# PIC32CX1025MTSH128S1 register map
Vendor: Microchip Technology; Series: PIC32CXMTSH; File version: 0
CPU: CM4 r0p1, little endian, MPU, FPU, 4 interrupt priority bits, 96 interrupts
Registers are 32-bit, read-write, reset 0x0 unless marked. A register's access mark holds for its fields unless they carry their own. Offsets are from the block's base; [hi:lo] are bit positions; {n}, {i} and the like mark numbered series.

## NVIC — Nested Vectored Interrupt Controller
Base 0xE000E100
{0x0+4i} ISER[{i}] (i=0..7) — Interrupt Set Enable Register
  [31:0] SETENA — Interrupt set enable bits
{0x80+4i} ICER[{i}] (i=0..7) — Interrupt Clear Enable Register
  [31:0] CLRENA — Interrupt clear-enable bits
{0x100+4i} ISPR[{i}] (i=0..7) — Interrupt Set Pending Register
  [31:0] SETPEND — Interrupt set-pending bits
{0x180+4i} ICPR[{i}] (i=0..7) — Interrupt Clear Pending Register
  [31:0] CLRPEND — Interrupt clear-pending bits
{0x200+4i} IABR[{i}] (i=0..7) ro — Interrupt Active bit Register
  [31:0] ACTIVE — Interrupt active flags
{0x300+i} IP[{i}] (i=0..239) 8-bit — Interrupt Priority Register
  [7:0] PRI — Priority of interrupt
0xE00 STIR wo — Software Trigger Interrupt Register
  [8:0] INTID — Indicates the interrupt to be triggered. The value written is (ExceptionNumber - 16)

## SCnSCB — System control not in SCB
Base 0xE000E000
0x04 ICTR ro — Interrupt Controller Type Register
  [3:0] INTLINESNUM — Total number of interrupt lines supported by an implementation, defined in groups of 32
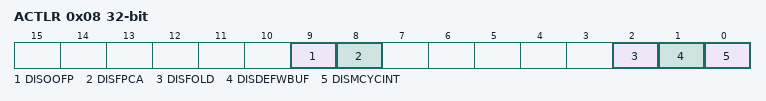
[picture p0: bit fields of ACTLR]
0x08 ACTLR — Auxiliary Control Register
  [9] DISOOFP — Disables floating point instructions completing out of order with respect to integer instructions
  [8] DISFPCA — Disable automatic update of CONTROL.FPCA
  [2] DISFOLD — Disables folding of IT instructions
  [1] DISDEFWBUF — Disables write buffer use during default memory map accesses
  [0] DISMCYCINT — Disables interruption of multi-cycle instructions

## SysTick — System timer
Base 0xE000E010
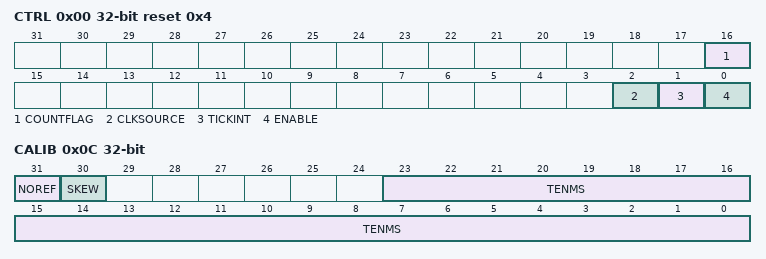
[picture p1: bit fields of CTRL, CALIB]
0x00 CTRL reset 0x4 — Control and Status Register
  [16] COUNTFLAG — Returns 1 if timer counted to 0 since last time this was read
  [2] CLKSOURCE — Indicates the clock source
    0=External clock; 1=Processor clock
  [1] TICKINT — Enables SysTick exception request
    0=Counting down to 0 does not affect the SysTick exception status; 1=Counting down to 0 changes the SysTick exception status to pending
  [0] ENABLE — Enables the counter
    0=Counter is disabled; 1=Counter is operating
0x04 LOAD — Reload Value Register
  [23:0] RELOAD — Value to load into the SysTick Current Value Register when the counter reaches 0
0x08 VAL — Current Value Register
  [31:0] CURRENT — Current value at the time the register is accessed
0x0C CALIB ro — Calibration Register
  [31] NOREF — Indicates whether the device provides a reference clock to the processor
    0=The reference clock is implemented; 1=The reference clock is not implemented
  [30] SKEW — Indicates whether the TENMS value is exact
    0=10ms calibration value is exact; 1=10ms calibration value is inexact, because of the clock frequency
  [23:0] TENMS — Reload value to use for 10ms timing

## TPI — Trace Port Interface Register
Base 0xE0040000
0x00 SSPSR ro — Supported Parallel Port Size Register
0x04 CSPSR — Current Parallel Port Size Register
0x10 ACPR — Asynchronous Clock Prescaler Register
  [12:0] PRESCALER — Divisor for TRACECLKIN is Prescaler + 1
0xF0 SPPR — Selected Pin Protocol Register
  [1:0] TXMODE
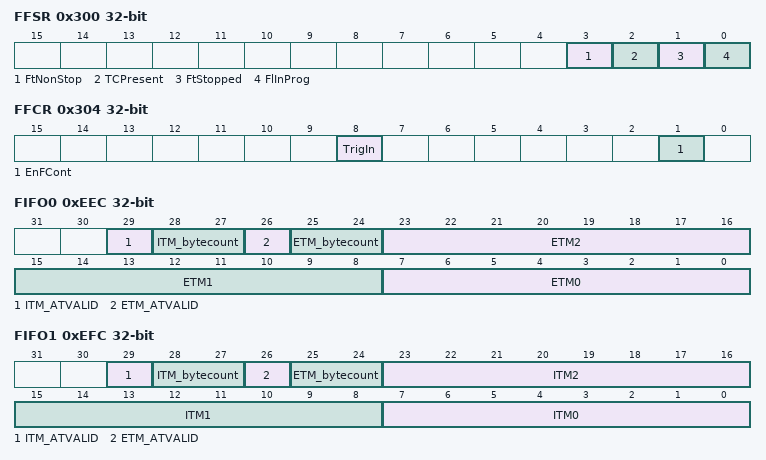
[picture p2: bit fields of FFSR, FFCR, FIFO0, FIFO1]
0x300 FFSR ro — Formatter and Flush Status Register
  [3] FtNonStop — Formatter cannot be stopped
  [2] TCPresent — This bit always reads zero
  [1] FtStopped — This bit always reads zero
  [0] FlInProg — This bit always reads zero
0x304 FFCR — Formatter and Flush Control Register
  [8] TrigIn — This bit Reads-As-One (RAO), specifying that triggers are inserted when a trigger pin is asserted
  [1] EnFCont — Enable continuous formatting
0x308 FSCR ro — Formatter Synchronization Counter Register
0xEE8 TRIGGER ro
  [0] TRIGGER — When read, this bit returns the TRIGGER input
0xEEC FIFO0 ro — Integration ETM Data
  [29] ITM_ATVALID, [28:27] ITM_bytecount, [26] ETM_ATVALID, [25:24] ETM_bytecount, [23:16] ETM2, [15:8] ETM1, [7:0] ETM0
0xEF0 ITATBCTR2 ro
  [0] ATREADY
0xEF8 ITATBCTR0 ro
  [0] ATREADY
0xEFC FIFO1 ro — Integration ITM Data
  [29] ITM_ATVALID, [28:27] ITM_bytecount, [26] ETM_ATVALID, [25:24] ETM_bytecount, [23:16] ITM2, [15:8] ITM1, [7:0] ITM0
0xF00 ITCTRL — Integration Mode Control
  [0] Mode
0xFA0 CLAIMSET — Claim tag set
0xFA4 CLAIMCLR — Claim tag clear
0xFB0 LAR wo — Software Lock Access Register
  [31:0] KEY — Lock access control
    0xC5ACCE55=UNLOCK (Unlock key value)
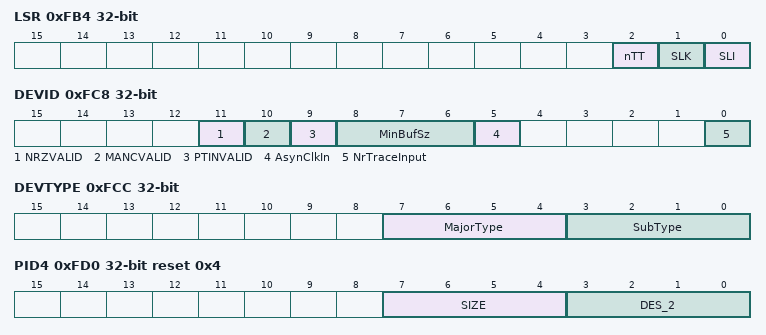
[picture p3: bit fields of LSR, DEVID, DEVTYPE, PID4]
0xFB4 LSR ro — Software Lock Status Register
  [2] nTT — Not thirty-two bit
  [1] SLK — Software Lock status
  [0] SLI — Software Lock implemented
0xFC8 DEVID ro — TPI_DEVID
  [11] NRZVALID, [10] MANCVALID, [9] PTINVALID, [8:6] MinBufSz, [5] AsynClkIn, [0] NrTraceInput
0xFCC DEVTYPE ro — TPI_DEVTYPE
  [7:4] MajorType, [3:0] SubType
0xFD0 PID4 ro reset 0x4 — Peripheral Identification Register 4
  [7:4] SIZE — 4KB count
  [3:0] DES_2 — JEP106 continuation code
{0xFC0+4i} PID{i} ro (i=5..7) — Peripheral Identification Register {i}
0xFE0 PID0 ro reset 0xA1 — Peripheral Identification Register 0
  [7:0] PART_0 — Part number bits[7:0]
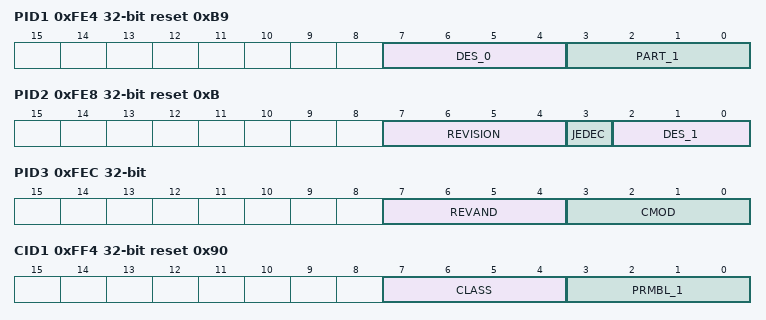
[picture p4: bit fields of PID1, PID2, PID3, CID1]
0xFE4 PID1 ro reset 0xB9 — Peripheral Identification Register 1
  [7:4] DES_0 — JEP106 identification code bits [3:0]
  [3:0] PART_1 — Part number bits[11:8]
0xFE8 PID2 ro reset 0xB — Peripheral Identification Register 2
  [7:4] REVISION — Component revision
  [3] JEDEC — JEDEC assignee value is used
  [2:0] DES_1 — JEP106 identification code bits[6:4]
0xFEC PID3 ro — Peripheral Identification Register 3
  [7:4] REVAND
  [3:0] CMOD — Customer Modified
0xFF0 CID0 ro reset 0xD — Component Identification Register 0
  [7:0] PRMBL_0 — CoreSight component identification preamble
0xFF4 CID1 ro reset 0x90 — Component Identification Register 1
  [7:4] CLASS — CoreSight component class
  [3:0] PRMBL_1 — CoreSight component identification preamble
0xFF8 CID2 ro reset 0x5 — Component Identification Register 2
  [7:0] PRMBL_2 — CoreSight component identification preamble
0xFFC CID3 ro reset 0xB1 — Component Identification Register 3
  [7:0] PRMBL_3 — CoreSight component identification preamble

## Notices in the file
Copyright (c) 2025 Microchip Technology Inc.
SPDX-License-Identifier: Apache-2.0
Licensed under the Apache License, Version 2.0 (the "License");
you may not use this file except in compliance with the License.
You may obtain a copy of the License at
http://www.apache.org/licenses/LICENSE-2.0
Unless required by applicable law or agreed to in writing, software
distributed under the License is distributed on an "AS IS" BASIS,
WITHOUT WARRANTIES OR CONDITIONS OF ANY KIND, either express or implied.
See the License for the specific language governing permissions and
limitations under the License.
